# CORE_AP register map
Vendor: Texas Instruments
Peripheral module from a debugger description file (folder omap36xx).
Registers are 32-bit, read-only, reset 0x0 unless marked. A register's access mark holds for its fields unless they carry their own. Offsets are as the file gives them; lines under a group give offsets from that group; [hi:lo] are bit positions; {n}, {i} and the like mark numbered series; 'fields as' and 'values as' point back to an identical list; <NAME> marks a mode.

## CORE_AP
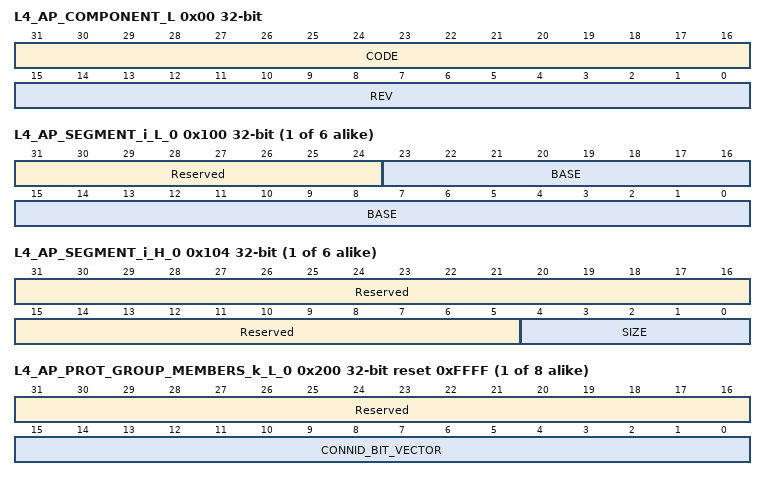
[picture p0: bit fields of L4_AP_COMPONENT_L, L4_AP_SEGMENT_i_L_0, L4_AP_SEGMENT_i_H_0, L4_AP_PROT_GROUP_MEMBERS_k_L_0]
0x00 L4_AP_COMPONENT_L reset not defined — Contains a component code and revision, which are used to identify the hardware of the component.
  [31:16] CODE — Interconnect code.
  [15:0] REV — Component revision code.
0x04 L4_AP_COMPONENT_H — Contains a component code and revision, which are used to identify the hardware of the component.
  [31:0] Reserved — Read returns 0
{0x100+8i} L4_AP_SEGMENT_i_L_{i} (reset mask 0xFF000000) (i=0..5) — Define the base address of each segments
  [31:24] Reserved — Read returns 0.
  [23:0] BASE — The base address of the segment (with 0s from bit 0 to bit SIZE-1).
{0x104+8i} L4_AP_SEGMENT_i_H_{i} (reset mask 0xFFFFFFE0) (i=0..5) — Define the size of each segments
  [31:5] Reserved — Read returns 0.
  [4:0] SIZE — Segment size is a power of 2, where 2^SIZE is the byte size of a segment (all segment registers use the same size).
{0x200+8i} L4_AP_PROT_GROUP_MEMBERS_k_L_{i} reset 0xFFFF (i=0..7) — Define connID bit vectors for a protection group.
  [31:16] Reserved — Read returns 0
  [15:0] CONNID_BIT_VECTOR — A bit of 1 in position n means that connID n is allowed in this protection group. Illegal connIDs have their bits set to 0s.
{0x204+8i} L4_AP_PROT_GROUP_MEMBERS_k_H_{i} (i=0..7) — Define connID bit vectors for a protection group.
  [31:0] Reserved — Read returns 0's
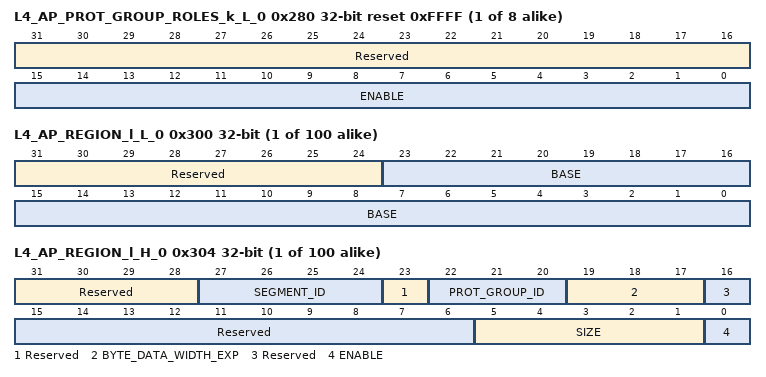
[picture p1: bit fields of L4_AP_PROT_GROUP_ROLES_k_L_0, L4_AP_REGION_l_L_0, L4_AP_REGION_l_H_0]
{0x280+8i} L4_AP_PROT_GROUP_ROLES_k_L_{i} reset 0xFFFF (i=0..7) — Define MReqInfo bit vectors for a protection group.
  [31:16] Reserved — Read returns 0
  [15:0] ENABLE — Setting of type acces allowed for the group of initiators see.
{0x284+8i} L4_AP_PROT_GROUP_ROLES_k_H_{i} (i=0..7) — Define connID bit vectors for a protection group.
  [31:0] Reserved — Read returns 0's
{0x300+8i} L4_AP_REGION_l_L_{i} (reset mask 0xFF000000) (i=0..99) — Define the base address of the region in respect to the segment it belongs to.
  [31:24] Reserved — Read returns 0.
  [23:0] BASE — Sets the base address of this region relative to its segment base.
{0x304+8i} L4_AP_REGION_l_H_{i} access per field (reset mask 0xF081FFC0) (i=0..99) — Define the size, protection group^and segment ID of the region
  [31:28] Reserved ro — Read returns 0
  [27:24] SEGMENT_ID ro — Identifies the segment to which the region is part of.
  [23] Reserved ro — Read returns 0.
  [22:20] PROT_GROUP_ID rw — The protection group containing this region.
  [19:17] BYTE_DATA_WIDTH_EXP ro — The target OCP data byte width is 2^(BYTE_DATA_WIDTH_EXP) bytes. The value of this field is derived from the target OCP data_wdth parameter.
  [16:6] Reserved ro — Read returns 0.
  [5:1] SIZE ro — Define the size of the region in bytes. 2^SIZE equals the region.
  [0] ENABLE ro — 0x0: Disable the region, no access allows0x1: Enable the region, with access as define in registers
